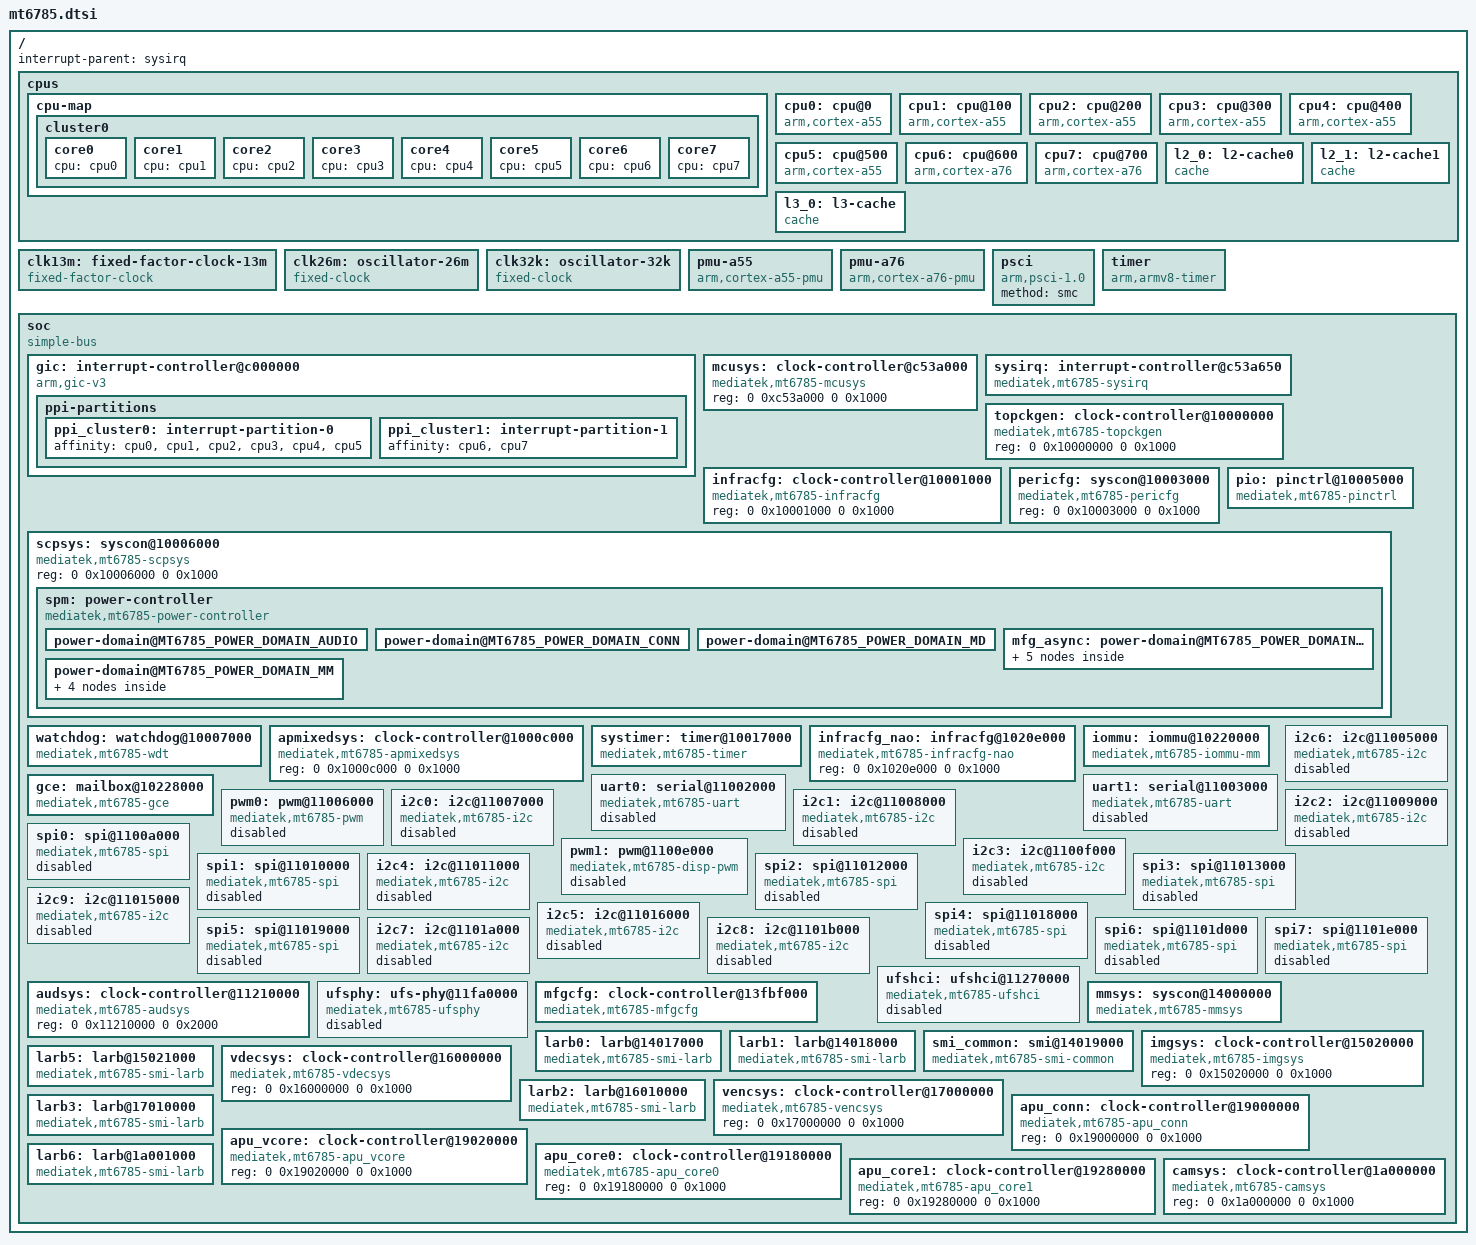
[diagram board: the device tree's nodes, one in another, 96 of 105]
// SPDX-License-Identifier: (GPL-2.0 OR MIT)
/*
 * Copyright (c) 2025 Dinolek <git@dinolek.me>
 */

#include <dt-bindings/clock/mediatek,mt6785-clk.h>
#include <dt-bindings/gce/mediatek,mt6785-gce.h>
#include <dt-bindings/interrupt-controller/arm-gic.h>
#include <dt-bindings/interrupt-controller/irq.h>
#include <dt-bindings/memory/mediatek,mt6785-memory-port.h>
#include <dt-bindings/pinctrl/mediatek,mt6785-pinfunc.h>
#include <dt-bindings/power/mediatek,mt6785-power.h>
#include <dt-bindings/reset/mediatek,mt6785-resets.h>

/ {
	#address-cells = <2>;
	#size-cells = <2>;
	interrupt-parent = <&sysirq>;

	cpus {
		#address-cells = <1>;
		#size-cells = <0>;

		cpu-map {
			cluster0 {
				core0 {
					cpu = <&cpu0>;
				};

				core1 {
					cpu = <&cpu1>;
				};

				core2 {
					cpu = <&cpu2>;
				};

				core3 {
					cpu = <&cpu3>;
				};

				core4 {
					cpu = <&cpu4>;
				};

				core5 {
					cpu = <&cpu5>;
				};

				core6 {
					cpu = <&cpu6>;
				};

				core7 {
					cpu = <&cpu7>;
				};
			};
		};

		cpu0: cpu@0 {
			device_type = "cpu";
			compatible = "arm,cortex-a55";
			reg = <0x000>;
			enable-method = "psci";
			dynamic-power-coefficient = <84>;
			capacity-dmips-mhz = <284>;
			i-cache-size = <32768>;
			i-cache-line-size = <64>;
			i-cache-sets = <128>;
			d-cache-size = <32768>;
			d-cache-line-size = <64>;
			d-cache-sets = <128>;
			next-level-cache = <&l2_0>;
		};

		cpu1: cpu@100 {
			device_type = "cpu";
			compatible = "arm,cortex-a55";
			reg = <0x100>;
			enable-method = "psci";
			dynamic-power-coefficient = <84>;
			capacity-dmips-mhz = <284>;
			i-cache-size = <32768>;
			i-cache-line-size = <64>;
			i-cache-sets = <128>;
			d-cache-size = <32768>;
			d-cache-line-size = <64>;
			d-cache-sets = <128>;
			next-level-cache = <&l2_0>;
		};

		cpu2: cpu@200 {
			device_type = "cpu";
			compatible = "arm,cortex-a55";
			reg = <0x200>;
			enable-method = "psci";
			dynamic-power-coefficient = <84>;
			capacity-dmips-mhz = <284>;
			i-cache-size = <32768>;
			i-cache-line-size = <64>;
			i-cache-sets = <128>;
			d-cache-size = <32768>;
			d-cache-line-size = <64>;
			d-cache-sets = <128>;
			next-level-cache = <&l2_0>;
		};

		cpu3: cpu@300 {
			device_type = "cpu";
			compatible = "arm,cortex-a55";
			reg = <0x300>;
			enable-method = "psci";
			dynamic-power-coefficient = <84>;
			capacity-dmips-mhz = <284>;
			i-cache-size = <32768>;
			i-cache-line-size = <64>;
			i-cache-sets = <128>;
			d-cache-size = <32768>;
			d-cache-line-size = <64>;
			d-cache-sets = <128>;
			next-level-cache = <&l2_0>;
		};

		cpu4: cpu@400 {
			device_type = "cpu";
			compatible = "arm,cortex-a55";
			reg = <0x400>;
			enable-method = "psci";
			dynamic-power-coefficient = <84>;
			capacity-dmips-mhz = <284>;
			i-cache-size = <32768>;
			i-cache-line-size = <64>;
			i-cache-sets = <128>;
			d-cache-size = <32768>;
			d-cache-line-size = <64>;
			d-cache-sets = <128>;
			next-level-cache = <&l2_0>;
		};

		cpu5: cpu@500 {
			device_type = "cpu";
			compatible = "arm,cortex-a55";
			reg = <0x500>;
			enable-method = "psci";
			dynamic-power-coefficient = <84>;
			capacity-dmips-mhz = <284>;
			i-cache-size = <32768>;
			i-cache-line-size = <64>;
			i-cache-sets = <128>;
			d-cache-size = <32768>;
			d-cache-line-size = <64>;
			d-cache-sets = <128>;
			next-level-cache = <&l2_0>;
		};

		cpu6: cpu@600 {
			device_type = "cpu";
			compatible = "arm,cortex-a76";
			reg = <0x600>;
			enable-method = "psci";
			dynamic-power-coefficient = <275>;
			capacity-dmips-mhz = <1024>;
			i-cache-size = <65536>;
			i-cache-line-size = <64>;
			i-cache-sets = <256>;
			d-cache-size = <65536>;
			d-cache-line-size = <64>;
			d-cache-sets = <256>;
			next-level-cache = <&l2_1>;
		};

		cpu7: cpu@700 {
			device_type = "cpu";
			compatible = "arm,cortex-a76";
			reg = <0x700>;
			enable-method = "psci";
			dynamic-power-coefficient = <275>;
			capacity-dmips-mhz = <1024>;
			i-cache-size = <65536>;
			i-cache-line-size = <64>;
			i-cache-sets = <256>;
			d-cache-size = <65536>;
			d-cache-line-size = <64>;
			d-cache-sets = <256>;
			next-level-cache = <&l2_1>;
		};

		l2_0: l2-cache0 {
			compatible = "cache";
			cache-level = <2>;
			cache-size = <131072>;
			cache-line-size = <64>;
			cache-sets = <512>;
			next-level-cache = <&l3_0>;
			cache-unified;
		};

		l2_1: l2-cache1 {
			compatible = "cache";
			cache-level = <2>;
			cache-size = <262144>;
			cache-line-size = <64>;
			cache-sets = <512>;
			next-level-cache = <&l3_0>;
			cache-unified;
		};

		l3_0: l3-cache {
			compatible = "cache";
			cache-level = <3>;
			cache-size = <1048576>;
			cache-line-size = <64>;
			cache-sets = <1024>;
			cache-unified;
		};
	};

	clk13m: fixed-factor-clock-13m {
		compatible = "fixed-factor-clock";
		#clock-cells = <0>;
		clocks = <&clk26m>;
		clock-div = <2>;
		clock-mult = <1>;
		clock-output-names = "clk13m";
	};

	clk26m: oscillator-26m {
		compatible = "fixed-clock";
		#clock-cells = <0>;
		clock-frequency = <26000000>;
		clock-output-names = "clk26m";
	};

	clk32k: oscillator-32k {
		compatible = "fixed-clock";
		#clock-cells = <0>;
		clock-frequency = <32768>;
		clock-output-names = "clk32k";
	};

	pmu-a55 {
		compatible = "arm,cortex-a55-pmu";
		interrupt-parent = <&gic>;
		interrupts = <GIC_PPI 7 IRQ_TYPE_LEVEL_LOW &ppi_cluster0>;
	};

	pmu-a76 {
		compatible = "arm,cortex-a76-pmu";
		interrupt-parent = <&gic>;
		interrupts = <GIC_PPI 7 IRQ_TYPE_LEVEL_LOW &ppi_cluster1>;
	};

	psci {
		compatible = "arm,psci-1.0";
		method = "smc";
	};

	timer {
		compatible = "arm,armv8-timer";
		interrupt-parent = <&gic>;
		interrupts = <GIC_PPI 13 IRQ_TYPE_LEVEL_LOW 0>,
			     <GIC_PPI 14 IRQ_TYPE_LEVEL_LOW 0>,
			     <GIC_PPI 11 IRQ_TYPE_LEVEL_LOW 0>,
			     <GIC_PPI 10 IRQ_TYPE_LEVEL_LOW 0>;
	};

	soc {
		#address-cells = <2>;
		#size-cells = <2>;
		compatible = "simple-bus";
		ranges;

		gic: interrupt-controller@c000000 {
			compatible = "arm,gic-v3";
			#interrupt-cells = <4>;
			#redistributor-regions = <1>;
			interrupt-parent = <&gic>;
			interrupt-controller;
			reg = <0 0x0c000000 0 0x40000>, <0 0x0c040000 0 0x200000>;
			interrupts = <GIC_PPI 9 IRQ_TYPE_LEVEL_HIGH 0>;

			ppi-partitions {
				ppi_cluster0: interrupt-partition-0 {
					affinity = <&cpu0 &cpu1 &cpu2 &cpu3 &cpu4 &cpu5>;
				};

				ppi_cluster1: interrupt-partition-1 {
					affinity = <&cpu6 &cpu7>;
				};
			};
		};

		mcusys: clock-controller@c53a000 {
			compatible = "mediatek,mt6785-mcusys", "syscon";
			reg = <0 0xc53a000 0 0x1000>;
			#clock-cells = <1>;
		};

		sysirq: interrupt-controller@c53a650 {
			compatible = "mediatek,mt6785-sysirq", "mediatek,mt6577-sysirq";
			interrupt-controller;
			#interrupt-cells = <3>;
			interrupt-parent = <&gic>;
			reg = <0 0x0c53a650 0 0x50>;
		};

		topckgen: clock-controller@10000000 {
			compatible = "mediatek,mt6785-topckgen", "syscon";
			reg = <0 0x10000000 0 0x1000>;
			#clock-cells = <1>;
		};

		infracfg: clock-controller@10001000 {
			compatible = "mediatek,mt6785-infracfg", "syscon";
			reg = <0 0x10001000 0 0x1000>;
			#clock-cells = <1>;
			#reset-cells = <1>;
		};

		pericfg: syscon@10003000 {
			compatible = "mediatek,mt6785-pericfg", "syscon";
			reg = <0 0x10003000 0 0x1000>;
		};

		pio: pinctrl@10005000 {
			compatible = "mediatek,mt6785-pinctrl";
			reg = <0 0x10005000 0 0x1000>,
			      <0 0x11c20000 0 0x1000>,
			      <0 0x11d10000 0 0x1000>,
			      <0 0x11e20000 0 0x1000>,
			      <0 0x11e70000 0 0x1000>,
			      <0 0x11ea0000 0 0x1000>,
			      <0 0x11f20000 0 0x1000>,
			      <0 0x11f30000 0 0x1000>,
			      <0 0x1000b000 0 0x1000>;
			reg-names = "base", "rm", "br", "bl", "lb", "rt", "lt", "tl",
				    "eint";
			interrupts = <GIC_SPI 204 IRQ_TYPE_LEVEL_HIGH>;
			gpio-controller;
			#gpio-cells = <2>;
			gpio-ranges = <&pio 0 0 203>;
			interrupt-controller;
			#interrupt-cells = <2>;
		};

		scpsys: syscon@10006000 {
			compatible = "mediatek,mt6785-scpsys", "syscon", "simple-mfd";
			reg = <0 0x10006000 0 0x1000>;

			spm: power-controller {
				compatible = "mediatek,mt6785-power-controller";
				#address-cells = <1>;
				#size-cells = <0>;
				#power-domain-cells = <1>;

				power-domain@MT6785_POWER_DOMAIN_AUDIO {
					reg = <MT6785_POWER_DOMAIN_AUDIO>;
					clocks = <&infracfg CLK_INFRA_AUDIO_26M>;
					clock-names = "audio";
					mediatek,infracfg = <&infracfg>;
					#power-domain-cells = <0>;
				};

				power-domain@MT6785_POWER_DOMAIN_CONN {
					reg = <MT6785_POWER_DOMAIN_CONN>;
					mediatek,infracfg = <&infracfg>;
					mediatek,smi = <&smi_common>;
					#power-domain-cells = <0>;
				};

				power-domain@MT6785_POWER_DOMAIN_MD {
					reg = <MT6785_POWER_DOMAIN_MD>;
					mediatek,infracfg = <&infracfg>;
					#power-domain-cells = <0>;
				};

				mfg_async: power-domain@MT6785_POWER_DOMAIN_MFG_ASYNC {
					reg = <MT6785_POWER_DOMAIN_MFG_ASYNC>;
					clocks = <&topckgen CLK_TOP_MFG>;
					clock-names = "mfg";
					#address-cells = <1>;
					#size-cells = <0>;
					#power-domain-cells = <1>;

					mfg: power-domain@MT6785_POWER_DOMAIN_MFG {
						reg = <MT6785_POWER_DOMAIN_MFG>;
						mediatek,infracfg = <&infracfg>;
						#address-cells = <1>;
						#size-cells = <0>;
						#power-domain-cells = <1>;

						power-domain@MT6785_POWER_DOMAIN_MFG_CORE0 {
							reg = <MT6785_POWER_DOMAIN_MFG_CORE0>;
							#power-domain-cells = <0>;
						};

						power-domain@MT6785_POWER_DOMAIN_MFG_CORE1 {
							reg = <MT6785_POWER_DOMAIN_MFG_CORE1>;
							#power-domain-cells = <0>;
						};

						power-domain@MT6785_POWER_DOMAIN_MFG_CORE2 {
							reg = <MT6785_POWER_DOMAIN_MFG_CORE2>;
							#power-domain-cells = <0>;
						};

						power-domain@MT6785_POWER_DOMAIN_MFG_CORE3 {
							reg = <MT6785_POWER_DOMAIN_MFG_CORE3>;
							#power-domain-cells = <0>;
						};
					};
				};

				power-domain@MT6785_POWER_DOMAIN_MM {
					reg = <MT6785_POWER_DOMAIN_MM>;
					clocks = <&topckgen CLK_TOP_MM>;
					clock-names = "mm";
					mediatek,infracfg-nao = <&infracfg_nao>;
					mediatek,infracfg = <&infracfg>;
					mediatek,smi = <&smi_common>;
					#address-cells = <1>;
					#size-cells = <0>;
					#power-domain-cells = <1>;

					power-domain@MT6785_POWER_DOMAIN_CAM {
						reg = <MT6785_POWER_DOMAIN_CAM>;
						clocks = <&topckgen CLK_TOP_CAM>;
						clock-names = "cam";
						mediatek,infracfg = <&infracfg>;
						mediatek,smi = <&smi_common>;
						#power-domain-cells = <0>;
					};

					power-domain@MT6785_POWER_DOMAIN_ISP {
						reg = <MT6785_POWER_DOMAIN_ISP>;
						clocks = <&topckgen CLK_TOP_IMG>;
						clock-names = "isp";
						mediatek,infracfg = <&infracfg>;
						mediatek,smi = <&smi_common>;
						#power-domain-cells = <0>;
					};

					power-domain@MT6785_POWER_DOMAIN_VDEC {
						reg = <MT6785_POWER_DOMAIN_VDEC>;
						clocks = <&topckgen CLK_TOP_VDEC>;
						clock-names = "vdec";
						mediatek,infracfg = <&infracfg>;
						mediatek,smi = <&smi_common>;
						#power-domain-cells = <0>;
					};

					power-domain@MT6785_POWER_DOMAIN_VENC {
						reg = <MT6785_POWER_DOMAIN_VENC>;
						clocks = <&topckgen CLK_TOP_VENC>;
						clock-names = "venc";
						mediatek,infracfg = <&infracfg>;
						mediatek,smi = <&smi_common>;
						#power-domain-cells = <0>;
					};
				};
			};
		};

		watchdog: watchdog@10007000 {
			compatible = "mediatek,mt6785-wdt";
			reg = <0 0x10007000 0 0x1000>;
			interrupts = <GIC_SPI 72 IRQ_TYPE_LEVEL_LOW>;
			#reset-cells = <1>;
		};

		apmixedsys: clock-controller@1000c000 {
			compatible = "mediatek,mt6785-apmixedsys", "syscon";
			reg = <0 0x1000c000 0 0x1000>;
			#clock-cells = <1>;
		};

		systimer: timer@10017000 {
			compatible = "mediatek,mt6785-timer", "mediatek,mt6765-timer";
			reg = <0 0x10017000 0 0x1000>;
			interrupts = <GIC_SPI 224 IRQ_TYPE_LEVEL_HIGH>;
			clocks = <&clk13m>;
		};

		infracfg_nao: infracfg@1020e000 {
			compatible = "mediatek,mt6785-infracfg-nao", "syscon";
			reg = <0 0x1020e000 0 0x1000>;
			#clock-cells = <1>;
		};

		iommu: iommu@10220000 {
			compatible = "mediatek,mt6785-iommu-mm";
			reg = <0 0x10220000 0 0x4000>;
			interrupts = <GIC_SPI 187 IRQ_TYPE_LEVEL_LOW>;
			mediatek,larbs = <&larb0>, <&larb1>, <&larb2>,
					 <&larb3>, <&larb5>, <&larb6>;
			#iommu-cells = <1>;
		};

		gce: mailbox@10228000 {
			compatible = "mediatek,mt6785-gce", "mediatek,mt6779-gce";
			reg = <0 0x10228000 0 0x4000>;
			clocks = <&infracfg CLK_INFRA_GCE>;
			clock-names = "gce";
			interrupts = <GIC_SPI 185 IRQ_TYPE_LEVEL_LOW>;
			#mbox-cells = <2>;
		};

		uart0: serial@11002000 {
			compatible = "mediatek,mt6785-uart", "mediatek,mt6577-uart";
			reg = <0 0x11002000 0 0x1000>;
			interrupts = <GIC_SPI 115 IRQ_TYPE_LEVEL_LOW>;
			clocks = <&clk26m>, <&infracfg CLK_INFRA_UART0>;
			clock-names = "baud", "bus";
			status = "disabled";
		};

		uart1: serial@11003000 {
			compatible = "mediatek,mt6785-uart", "mediatek,mt6577-uart";
			reg = <0 0x11003000 0 0x1000>;
			interrupts = <GIC_SPI 116 IRQ_TYPE_LEVEL_LOW>;
			clocks = <&clk26m>, <&infracfg CLK_INFRA_UART1>;
			clock-names = "baud", "bus";
			status = "disabled";
		};

		i2c6: i2c@11005000 {
			compatible = "mediatek,mt6785-i2c", "mediatek,mt8186-i2c";
			reg = <0 0x11005000 0 0x1000>, <0 0x11000580 0 0x100>;
			interrupts = <GIC_SPI 111 IRQ_TYPE_LEVEL_LOW>;
			clocks = <&infracfg CLK_INFRA_I2C_AP>,
				 <&infracfg CLK_INFRA_AP_DMA>;
			clock-names = "main", "dma";
			clock-div = <5>;
			#address-cells = <1>;
			#size-cells = <0>;
			status = "disabled";
		};

		pwm0: pwm@11006000 {
			compatible = "mediatek,mt6785-pwm", "mediatek,mt8183-pwm";
			reg = <0 0x11006000 0 0x1000>;
			#pwm-cells = <2>;
			interrupts = <GIC_SPI 200 IRQ_TYPE_LEVEL_LOW>;
			clocks = <&infracfg CLK_INFRA_PWM>,
				 <&infracfg CLK_INFRA_PWM_HCLK>,
				 <&infracfg CLK_INFRA_PWM1>,
				 <&infracfg CLK_INFRA_PWM2>,
				 <&infracfg CLK_INFRA_PWM3>,
				 <&infracfg CLK_INFRA_PWM4>;
			clock-names = "top", "main", "pwm1", "pwm2", "pwm3", "pwm4";
			status = "disabled";
		};

		i2c0: i2c@11007000 {
			compatible = "mediatek,mt6785-i2c", "mediatek,mt8186-i2c";
			reg = <0 0x11007000 0 0x1000>, <0 0x11000080 0 0x80>;
			interrupts = <GIC_SPI 105 IRQ_TYPE_LEVEL_LOW>;
			clocks = <&infracfg CLK_INFRA_I2C_AP>,
				 <&infracfg CLK_INFRA_AP_DMA>;
			clock-names = "main", "dma";
			clock-div = <5>;
			#address-cells = <1>;
			#size-cells = <0>;
			status = "disabled";
		};

		i2c1: i2c@11008000 {
			compatible = "mediatek,mt6785-i2c", "mediatek,mt8186-i2c";
			reg = <0 0x11008000 0 0x1000>, <0 0x11000100 0 0x80>;
			interrupts = <GIC_SPI 106 IRQ_TYPE_LEVEL_LOW>;
			clocks = <&infracfg CLK_INFRA_I2C_AP>,
				 <&infracfg CLK_INFRA_AP_DMA>;
			clock-names = "main", "dma";
			clock-div = <5>;
			#address-cells = <1>;
			#size-cells = <0>;
			status = "disabled";
		};

		i2c2: i2c@11009000 {
			compatible = "mediatek,mt6785-i2c", "mediatek,mt8186-i2c";
			reg = <0 0x11009000 0 0x1000>, <0 0x11000180 0 0x180>;
			interrupts = <GIC_SPI 107 IRQ_TYPE_LEVEL_LOW>;
			clocks = <&infracfg CLK_INFRA_I2C_AP>,
				 <&infracfg CLK_INFRA_AP_DMA>;
			clock-names = "main", "dma";
			clock-div = <5>;
			#address-cells = <1>;
			#size-cells = <0>;
			status = "disabled";
		};

		spi0: spi@1100a000 {
			compatible = "mediatek,mt6785-spi", "mediatek,mt6765-spi";
			#address-cells = <1>;
			#size-cells = <0>;
			reg = <0 0x1100a000 0 0x1000>;
			interrupts = <GIC_SPI 143 IRQ_TYPE_LEVEL_LOW>;
			clocks = <&topckgen CLK_TOP_MAINPLL_D5_D2>,
				 <&topckgen CLK_TOP_SPI>, <&infracfg CLK_INFRA_SPI0>;
			clock-names = "parent-clk", "sel-clk", "spi-clk";
			status = "disabled";
		};

		pwm1: pwm@1100e000 {
			compatible = "mediatek,mt6785-disp-pwm",
				     "mediatek,mt8183-disp-pwm";
			reg = <0 0x1100e000 0 0x1000>;
			interrupts = <GIC_SPI 151 IRQ_TYPE_LEVEL_LOW>;
			#pwm-cells = <2>;
			clocks = <&topckgen CLK_TOP_DISP_PWM>,
				 <&infracfg CLK_INFRA_DISP_PWM>;
			clock-names = "main", "mm";
			status = "disabled";
		};

		i2c3: i2c@1100f000 {
			compatible = "mediatek,mt6785-i2c", "mediatek,mt8186-i2c";
			reg = <0 0x1100f000 0 0x1000>, <0 0x11000300 0 0x80>;
			interrupts = <GIC_SPI 108 IRQ_TYPE_LEVEL_LOW>;
			clocks = <&infracfg CLK_INFRA_I2C_AP>,
				 <&infracfg CLK_INFRA_AP_DMA>;
			clock-names = "main", "dma";
			clock-div = <5>;
			#address-cells = <1>;
			#size-cells = <0>;
			status = "disabled";
		};

		spi1: spi@11010000 {
			compatible = "mediatek,mt6785-spi", "mediatek,mt6765-spi";
			#address-cells = <1>;
			#size-cells = <0>;
			reg = <0 0x11010000 0 0x1000>;
			interrupts = <GIC_SPI 147 IRQ_TYPE_LEVEL_LOW>;
			clocks = <&topckgen CLK_TOP_MAINPLL_D5_D2>,
				 <&topckgen CLK_TOP_SPI>, <&infracfg CLK_INFRA_SPI1>;
			clock-names = "parent-clk", "sel-clk", "spi-clk";
			status = "disabled";
		};

		i2c4: i2c@11011000 {
			compatible = "mediatek,mt6785-i2c", "mediatek,mt8186-i2c";
			reg = <0 0x11011000 0 0x1000>, <0 0x11000380 0 0x180>;
			interrupts = <GIC_SPI 109 IRQ_TYPE_LEVEL_LOW>;
			clocks = <&infracfg CLK_INFRA_I2C_AP>,
				 <&infracfg CLK_INFRA_AP_DMA>;
			clock-names = "main", "dma";
			clock-div = <5>;
			#address-cells = <1>;
			#size-cells = <0>;
			status = "disabled";
		};

		spi2: spi@11012000 {
			compatible = "mediatek,mt6785-spi", "mediatek,mt6765-spi";
			#address-cells = <1>;
			#size-cells = <0>;
			reg = <0 0x11012000 0 0x1000>;
			interrupts = <GIC_SPI 152 IRQ_TYPE_LEVEL_LOW>;
			clocks = <&topckgen CLK_TOP_MAINPLL_D5_D2>,
				 <&topckgen CLK_TOP_SPI>, <&infracfg CLK_INFRA_SPI2>;
			clock-names = "parent-clk", "sel-clk", "spi-clk";
			status = "disabled";
		};

		spi3: spi@11013000 {
			compatible = "mediatek,mt6785-spi", "mediatek,mt6765-spi";
			#address-cells = <1>;
			#size-cells = <0>;
			reg = <0 0x11013000 0 0x1000>;
			interrupts = <GIC_SPI 153 IRQ_TYPE_LEVEL_LOW>;
			clocks = <&topckgen CLK_TOP_MAINPLL_D5_D2>,
				 <&topckgen CLK_TOP_SPI>, <&infracfg CLK_INFRA_SPI3>;
			clock-names = "parent-clk", "sel-clk", "spi-clk";
			status = "disabled";
		};

		i2c9: i2c@11015000 {
			compatible = "mediatek,mt6785-i2c", "mediatek,mt8186-i2c";
			reg = <0 0x11015000 0 0x1000>, <0 0x11000800 0 0x80>;
			interrupts = <GIC_SPI 114 IRQ_TYPE_LEVEL_LOW>;
			clocks = <&infracfg CLK_INFRA_I2C_AP>,
				 <&infracfg CLK_INFRA_AP_DMA>;
			clock-names = "main", "dma";
			clock-div = <5>;
			#address-cells = <1>;
			#size-cells = <0>;
			status = "disabled";
		};

		i2c5: i2c@11016000 {
			compatible = "mediatek,mt6785-i2c", "mediatek,mt8186-i2c";
			reg = <0 0x11016000 0 0x1000>, <0 0x11000500 0 0x80>;
			interrupts = <GIC_SPI 110 IRQ_TYPE_LEVEL_LOW>;
			clocks = <&infracfg CLK_INFRA_I2C_AP>,
				 <&infracfg CLK_INFRA_AP_DMA>;
			clock-names = "main", "dma";
			clock-div = <5>;
			#address-cells = <1>;
			#size-cells = <0>;
			status = "disabled";
		};

		spi4: spi@11018000 {
			compatible = "mediatek,mt6785-spi", "mediatek,mt6765-spi";
			#address-cells = <1>;
			#size-cells = <0>;
			reg = <0 0x11018000 0 0x1000>;
			interrupts = <GIC_SPI 156 IRQ_TYPE_LEVEL_LOW>;
			clocks = <&topckgen CLK_TOP_MAINPLL_D5_D2>,
				 <&topckgen CLK_TOP_SPI>, <&infracfg CLK_INFRA_SPI4>;
			clock-names = "parent-clk", "sel-clk", "spi-clk";
			status = "disabled";
		};

		spi5: spi@11019000 {
			compatible = "mediatek,mt6785-spi", "mediatek,mt6765-spi";
			#address-cells = <1>;
			#size-cells = <0>;
			reg = <0 0x11019000 0 0x1000>;
			interrupts = <GIC_SPI 157 IRQ_TYPE_LEVEL_LOW>;
			clocks = <&topckgen CLK_TOP_MAINPLL_D5_D2>,
				 <&topckgen CLK_TOP_SPI>, <&infracfg CLK_INFRA_SPI5>;
			clock-names = "parent-clk", "sel-clk", "spi-clk";
			status = "disabled";
		};

		i2c7: i2c@1101a000 {
			compatible = "mediatek,mt6785-i2c", "mediatek,mt8186-i2c";
			reg = <0 0x1101a000 0 0x1000>, <0 0x11000680 0 0x100>;
			interrupts = <GIC_SPI 112 IRQ_TYPE_LEVEL_LOW>;
			clocks = <&infracfg CLK_INFRA_I2C_AP>,
				 <&infracfg CLK_INFRA_AP_DMA>;
			clock-names = "main", "dma";
			clock-div = <5>;
			#address-cells = <1>;
			#size-cells = <0>;
			status = "disabled";
		};

		i2c8: i2c@1101b000 {
			compatible = "mediatek,mt6785-i2c", "mediatek,mt8186-i2c";
			reg = <0 0x1101b000 0 0x1000>, <0 0x11000780 0 0x80>;
			interrupts = <GIC_SPI 113 IRQ_TYPE_LEVEL_LOW>;
			clocks = <&infracfg CLK_INFRA_I2C_AP>,
				 <&infracfg CLK_INFRA_AP_DMA>;
			clock-names = "main", "dma";
			clock-div = <5>;
			#address-cells = <1>;
			#size-cells = <0>;
			status = "disabled";
		};

		spi6: spi@1101d000 {
			compatible = "mediatek,mt6785-spi", "mediatek,mt6765-spi";
			#address-cells = <1>;
			#size-cells = <0>;
			reg = <0 0x1101d000 0 0x1000>;
			interrupts = <GIC_SPI 144 IRQ_TYPE_LEVEL_LOW>;
			clocks = <&topckgen CLK_TOP_MAINPLL_D5_D2>,
				 <&topckgen CLK_TOP_SPI>, <&infracfg CLK_INFRA_SPI6>;
			clock-names = "parent-clk", "sel-clk", "spi-clk";
			status = "disabled";
		};

		spi7: spi@1101e000 {
			compatible = "mediatek,mt6785-spi", "mediatek,mt6765-spi";
			#address-cells = <1>;
			#size-cells = <0>;
			reg = <0 0x1101e000 0 0x1000>;
			interrupts = <GIC_SPI 145 IRQ_TYPE_LEVEL_LOW>;
			clocks = <&topckgen CLK_TOP_MAINPLL_D5_D2>,
				 <&topckgen CLK_TOP_SPI>, <&infracfg CLK_INFRA_SPI7>;
			clock-names = "parent-clk", "sel-clk", "spi-clk";
			status = "disabled";
		};

		audsys: clock-controller@11210000 {
			compatible = "mediatek,mt6785-audsys", "syscon";
			reg = <0 0x11210000 0 0x2000>;
			#clock-cells = <1>;
		};

		ufshci: ufshci@11270000 {
			compatible = "mediatek,mt6785-ufshci";
			reg = <0 0x11270000 0 0x2300>;
			interrupts = <GIC_SPI 104 IRQ_TYPE_LEVEL_LOW>;
			phys = <&ufsphy>;

			clocks = <&infracfg CLK_INFRA_UFS>,
				 <&infracfg CLK_INFRA_UFS_AXI>,
				 <&infracfg CLK_INFRA_UFS_TICK>,
				 <&infracfg CLK_INFRA_UNIPRO_MBIST>,
				 <&infracfg CLK_INFRA_UNIPRO_TICK>;
			clock-names = "ufs", "ufs-axi", "ufs-tick", "unipro-mbist",
				      "unipro-tick";
			freq-table-hz = <0 0>, <0 0>, <0 0>, <0 0>, <0 0>;

			resets = <&infracfg MT6785_INFRA_UFS_HCI_RST>,
				 <&infracfg MT6785_INFRA_UFS_UNIPRO_RST>,
				 <&infracfg MT6785_INFRA_UFS_AES_RST>;
			reset-names = "hci_rst", "unipro_rst", "crypto_rst";

			status = "disabled";
		};

		ufsphy: ufs-phy@11fa0000 {
			compatible = "mediatek,mt6785-ufsphy", "mediatek,mt8183-ufsphy";
			reg = <0 0x11fa0000 0 0xc000>;
			clocks = <&infracfg CLK_INFRA_UNIPRO_SYS>,
				 <&infracfg CLK_INFRA_UFS_MP_SAP>;
			clock-names = "unipro", "mp";
			#phy-cells = <0>;
			status = "disabled";
		};

		mfgcfg: clock-controller@13fbf000 {
			compatible = "mediatek,mt6785-mfgcfg", "syscon";
			reg = <0 0x13fbf000 0 0x1000>;
			#clock-cells = <1>;
			power-domains = <&spm MT6785_POWER_DOMAIN_MFG>;
		};

		mmsys: syscon@14000000 {
			compatible = "mediatek,mt6785-mmsys", "syscon";
			reg = <0 0x14000000 0 0x1000>;
			#clock-cells = <1>;
			#reset-cells = <1>;
			mboxes = <&gce 0 CMDQ_THR_PRIO_HIGHEST>,
				 <&gce 1 CMDQ_THR_PRIO_HIGHEST>;
			mediatek,gce-client-reg = <&gce SUBSYS_1400XXXX 0 0x1000>;
		};

		larb0: larb@14017000 {
			compatible = "mediatek,mt6785-smi-larb";
			reg = <0 0x14017000 0 0x1000>;
			mediatek,smi = <&smi_common>;
			mediatek,larb-id = <0>;
			clocks = <&mmsys CLK_MM_SMI_LARB0>, <&mmsys CLK_MM_SMI_LARB0>;
			clock-names = "apb", "smi";
			power-domains = <&spm MT6785_POWER_DOMAIN_MM>;
		};

		larb1: larb@14018000 {
			compatible = "mediatek,mt6785-smi-larb";
			reg = <0 0x14018000 0 0x1000>;
			mediatek,smi = <&smi_common>;
			mediatek,larb-id = <1>;
			clocks = <&mmsys CLK_MM_SMI_LARB1>, <&mmsys CLK_MM_SMI_LARB1>;
			clock-names = "apb", "smi";
			power-domains = <&spm MT6785_POWER_DOMAIN_MM>;
		};

		smi_common: smi@14019000 {
			compatible = "mediatek,mt6785-smi-common",
				     "mediatek,mt6779-smi-common";
			reg = <0 0x14019000 0 0x1000>;
			clocks = <&mmsys CLK_MM_SMI_COMMON>, <&mmsys CLK_MM_SMI_COMMON>,
				 <&mmsys CLK_MM_GALS_COMM0>, <&mmsys CLK_MM_GALS_COMM1>;
			clock-names = "apb", "smi", "gals0", "gals1";
			power-domains = <&spm MT6785_POWER_DOMAIN_MM>;
		};

		imgsys: clock-controller@15020000 {
			compatible = "mediatek,mt6785-imgsys", "syscon";
			reg = <0 0x15020000 0 0x1000>;
			#clock-cells = <1>;
		};

		larb5: larb@15021000 {
			compatible = "mediatek,mt6785-smi-larb";
			reg = <0 0x15021000 0 0x1000>;
			mediatek,smi = <&smi_common>;
			mediatek,larb-id = <5>;
			clocks = <&imgsys CLK_IMG_LARB5>, <&imgsys CLK_IMG_LARB5>,
				 <&mmsys CLK_MM_GALS_IMG2MM>;
			clock-names = "apb", "smi", "gals";
			power-domains = <&spm MT6785_POWER_DOMAIN_ISP>;
		};

		vdecsys: clock-controller@16000000 {
			compatible = "mediatek,mt6785-vdecsys", "syscon";
			reg = <0 0x16000000 0 0x1000>;
			#clock-cells = <1>;
		};

		larb2: larb@16010000 {
			compatible = "mediatek,mt6785-smi-larb";
			reg = <0 0x16010000 0 0x1000>;
			mediatek,smi = <&smi_common>;
			mediatek,larb-id = <2>;
			clocks = <&vdecsys CLK_VDEC_MAIN>, <&vdecsys CLK_VDEC_LARB1>;
			clock-names = "apb", "smi";
			power-domains = <&spm MT6785_POWER_DOMAIN_VDEC>;
		};

		vencsys: clock-controller@17000000 {
			compatible = "mediatek,mt6785-vencsys", "syscon";
			reg = <0 0x17000000 0 0x1000>;
			#clock-cells = <1>;
		};

		larb3: larb@17010000 {
			compatible = "mediatek,mt6785-smi-larb";
			reg = <0 0x17010000 0 0x1000>;
			mediatek,smi = <&smi_common>;
			mediatek,larb-id = <3>;
			clocks = <&vencsys CLK_VENC_LARB>, <&vencsys CLK_VENC_LARB>;
			clock-names = "apb", "smi";
			power-domains = <&spm MT6785_POWER_DOMAIN_VENC>;
		};

		apu_conn: clock-controller@19000000 {
			compatible = "mediatek,mt6785-apu_conn", "syscon";
			reg = <0 0x19000000 0 0x1000>;
			#clock-cells = <1>;
		};

		apu_vcore: clock-controller@19020000 {
			compatible = "mediatek,mt6785-apu_vcore", "syscon";
			reg = <0 0x19020000 0 0x1000>;
			#clock-cells = <1>;
		};

		apu_core0: clock-controller@19180000 {
			compatible = "mediatek,mt6785-apu_core0", "syscon";
			reg = <0 0x19180000 0 0x1000>;
			#clock-cells = <1>;
		};

		apu_core1: clock-controller@19280000 {
			compatible = "mediatek,mt6785-apu_core1", "syscon";
			reg = <0 0x19280000 0 0x1000>;
			#clock-cells = <1>;
		};

		camsys: clock-controller@1a000000 {
			compatible = "mediatek,mt6785-camsys", "syscon";
			reg = <0 0x1a000000 0 0x1000>;
			#clock-cells = <1>;
		};

		larb6: larb@1a001000 {
			compatible = "mediatek,mt6785-smi-larb";
			reg = <0 0x1a001000 0 0x1000>;
			mediatek,smi = <&smi_common>;
			mediatek,larb-id = <6>;
			clocks = <&camsys CLK_CAM_LARB6>, <&camsys CLK_CAM_LARB6>,
				 <&mmsys CLK_MM_GALS_CAM2MM>;
			clock-names = "apb", "smi", "gals";
			power-domains = <&spm MT6785_POWER_DOMAIN_CAM>;
		};
	};
};
